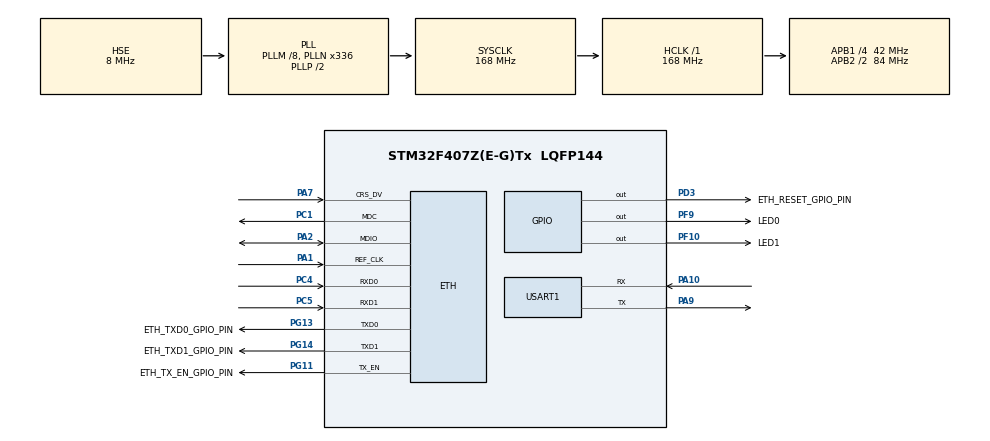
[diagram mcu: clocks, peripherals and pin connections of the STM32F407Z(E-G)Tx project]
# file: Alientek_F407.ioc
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ETH.MediaInterface=HAL_ETH_RMII_MODE
FREERTOS.Tasks01=defaultTask,24,128,StartDefaultTask,Default,NULL,Dynamic,NULL,NULL;myTask02,26,256,StartTask02,As weak,NULL,Static,myTask02Buffer,myTask02ControlBlock;myTask03,27,256,StartTask03,As weak,NULL,Static,myTask03Buffer,myTask03ControlBlock;myTask04,28,512,StartTask04,As weak,NULL,Static,myTask04Buffer,myTask04ControlBlock
FREERTOS.configENABLE_FPU=1
FREERTOS.configMAX_PRIORITIES=32
FREERTOS.configUSE_IDLE_HOOK=1
Mcu.Family=STM32F4
Mcu.Name=STM32F407Z(E-G)Tx
Mcu.Package=LQFP144
NVIC.PriorityGroup=NVIC_PRIORITYGROUP_4
NVIC.TIM1_TRG_COM_TIM11_IRQn=true\:5\:0\:false\:false\:true\:true\:true\:true\:true
NVIC.TIM6_DAC_IRQn=true\:15\:0\:false\:false\:true\:false\:false\:true\:true
NVIC.TimeBase=TIM6_DAC_IRQn
NVIC.TimeBaseIP=TIM6
PA1.Mode=RMII
PA1.Signal=ETH_REF_CLK
PA10.Mode=Asynchronous
PA10.Signal=USART1_RX
PA13.Mode=Trace_Asynchronous_SW
PA13.Signal=SYS_JTMS-SWDIO
PA14.Mode=Trace_Asynchronous_SW
PA14.Signal=SYS_JTCK-SWCLK
PA2.Mode=RMII
PA2.Signal=ETH_MDIO
PA7.Mode=RMII
PA7.Signal=ETH_CRS_DV
PA9.Mode=Asynchronous
PA9.Signal=USART1_TX
PB3.Mode=Trace_Asynchronous_SW
PB3.Signal=SYS_JTDO-SWO
PC1.Mode=RMII
PC1.Signal=ETH_MDC
PC14-OSC32_IN.Mode=LSE-External-Oscillator
PC14-OSC32_IN.Signal=RCC_OSC32_IN
PC15-OSC32_OUT.Mode=LSE-External-Oscillator
PC15-OSC32_OUT.Signal=RCC_OSC32_OUT
PC4.Mode=RMII
PC4.Signal=ETH_RXD0
PC5.Mode=RMII
PC5.Signal=ETH_RXD1
PD3.GPIO_Label=ETH_RESET_GPIO_PIN
PD3.GPIO_Speed=GPIO_SPEED_FREQ_MEDIUM
PD3.PinState=GPIO_PIN_SET
PD3.Signal=GPIO_Output
PF10.GPIO_Label=LED1
PF10.GPIO_Speed=GPIO_SPEED_FREQ_MEDIUM
PF10.PinState=GPIO_PIN_SET
PF10.Signal=GPIO_Output
PF9.GPIO_Label=LED0
PF9.GPIO_Speed=GPIO_SPEED_FREQ_MEDIUM
PF9.PinState=GPIO_PIN_SET
PF9.Signal=GPIO_Output
PG11.GPIO_Label=ETH_TX_EN_GPIO_PIN
PG11.Mode=RMII
PG11.Signal=ETH_TX_EN
PG13.GPIO_Label=ETH_TXD0_GPIO_PIN
PG13.Mode=RMII
PG13.Signal=ETH_TXD0
PG14.GPIO_Label=ETH_TXD1_GPIO_PIN
PG14.Mode=RMII
PG14.Signal=ETH_TXD1
PH0-OSC_IN.Mode=HSE-External-Oscillator
PH0-OSC_IN.Signal=RCC_OSC_IN
PH1-OSC_OUT.Mode=HSE-External-Oscillator
PH1-OSC_OUT.Signal=RCC_OSC_OUT
ProjectManager.HeapSize=0x800
ProjectManager.StackSize=0x800
ProjectManager.TargetToolchain=MDK-ARM V5.32
RCC.48MHZClocksFreq_Value=84000000
RCC.AHBFreq_Value=168000000
RCC.APB1CLKDivider=RCC_HCLK_DIV4
RCC.APB1Freq_Value=42000000
RCC.APB1TimFreq_Value=84000000
RCC.APB2CLKDivider=RCC_HCLK_DIV2
RCC.APB2Freq_Value=84000000
RCC.APB2TimFreq_Value=168000000
RCC.CortexFreq_Value=168000000
RCC.HCLKFreq_Value=168000000
RCC.HSE_VALUE=8000000
RCC.HSI_VALUE=16000000
RCC.PLLM=8
RCC.PLLN=336
RCC.PLLSourceVirtual=RCC_PLLSOURCE_HSE
RCC.SYSCLKFreq_VALUE=168000000
RCC.SYSCLKSource=RCC_SYSCLKSOURCE_PLLCLK
RCC.VCOOutputFreq_Value=336000000
TIM11.Period=4200-1
USART1.VirtualMode=VM_ASYNC
VP_FREERTOS_VS_CMSIS_V2.Mode=CMSIS_V2
VP_SYS_VS_tim6.Mode=TIM6
VP_TIM11_VS_ClockSourceINT.Mode=Enable_Timer
board=custom

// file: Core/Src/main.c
/* USER CODE BEGIN Header */
/**
  ******************************************************************************
  * @file           : main.c
  * @brief          : Main program body
  ******************************************************************************
  * @attention
  *
  * Copyright (c) 2026 STMicroelectronics.
  * All rights reserved.
  *
  * This software is licensed under terms that can be found in the LICENSE file
  * in the root directory of this software component.
  * If no LICENSE file comes with this software, it is provided AS-IS.
  *
  ******************************************************************************
  */
/* USER CODE END Header */
#include "main.h"
#include "cmsis_os.h"
#include "tim.h"
#include "usart.h"
#include "gpio.h"

void SystemClock_Config(void);
void MX_FREERTOS_Init(void);

int main(void)
{

  /* MCU Configuration--------------------------------------------------------*/

  /* Reset of all peripherals, Initializes the Flash interface and the Systick. */
  HAL_Init();

  /* Configure the system clock */
  SystemClock_Config();

  /* Initialize all configured peripherals */
  MX_GPIO_Init();
  MX_USART1_UART_Init();
  MX_TIM11_Init();

  /* Init scheduler */
  osKernelInitialize();  /* Call init function for freertos objects (in cmsis_os2.c) */
  MX_FREERTOS_Init();

  /* Start scheduler */
  osKernelStart();

  /* We should never get here as control is now taken by the scheduler */

  /* Infinite loop */
  while (1)
  {

  }
}

void SystemClock_Config(void)
{
  RCC_OscInitTypeDef RCC_OscInitStruct = {0};
  RCC_ClkInitTypeDef RCC_ClkInitStruct = {0};

  /** Configure the main internal regulator output voltage
  */
  __HAL_RCC_PWR_CLK_ENABLE();
  __HAL_PWR_VOLTAGESCALING_CONFIG(PWR_REGULATOR_VOLTAGE_SCALE1);

  /** Initializes the RCC Oscillators according to the specified parameters
  * in the RCC_OscInitTypeDef structure.
  */
  RCC_OscInitStruct.OscillatorType = RCC_OSCILLATORTYPE_HSE;
  RCC_OscInitStruct.HSEState = RCC_HSE_ON;
  RCC_OscInitStruct.PLL.PLLState = RCC_PLL_ON;
  RCC_OscInitStruct.PLL.PLLSource = RCC_PLLSOURCE_HSE;
  RCC_OscInitStruct.PLL.PLLM = 8;
  RCC_OscInitStruct.PLL.PLLN = 336;
  RCC_OscInitStruct.PLL.PLLP = RCC_PLLP_DIV2;
  RCC_OscInitStruct.PLL.PLLQ = 4;
  if (HAL_RCC_OscConfig(&RCC_OscInitStruct) != HAL_OK)
  {
    Error_Handler();
  }

  /** Initializes the CPU, AHB and APB buses clocks
  */
  RCC_ClkInitStruct.ClockType = RCC_CLOCKTYPE_HCLK|RCC_CLOCKTYPE_SYSCLK
                              |RCC_CLOCKTYPE_PCLK1|RCC_CLOCKTYPE_PCLK2;
  RCC_ClkInitStruct.SYSCLKSource = RCC_SYSCLKSOURCE_PLLCLK;
  RCC_ClkInitStruct.AHBCLKDivider = RCC_SYSCLK_DIV1;
  RCC_ClkInitStruct.APB1CLKDivider = RCC_HCLK_DIV4;
  RCC_ClkInitStruct.APB2CLKDivider = RCC_HCLK_DIV2;

  if (HAL_RCC_ClockConfig(&RCC_ClkInitStruct, FLASH_LATENCY_5) != HAL_OK)
  {
    Error_Handler();
  }
}

void HAL_TIM_PeriodElapsedCallback(TIM_HandleTypeDef *htim)
{
  if (htim->Instance == TIM6)
  {
    HAL_IncTick();
  }
}

void Error_Handler(void)
{
  __disable_irq();
  while (1)
  {
  }
}

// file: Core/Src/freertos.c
/* USER CODE BEGIN Header */
/**
  ******************************************************************************
  * File Name          : freertos.c
  * Description        : Code for freertos applications
  ******************************************************************************
  * @attention
  *
  * Copyright (c) 2026 STMicroelectronics.
  * All rights reserved.
  *
  * This software is licensed under terms that can be found in the LICENSE file
  * in the root directory of this software component.
  * If no LICENSE file comes with this software, it is provided AS-IS.
  *
  ******************************************************************************
  */
/* USER CODE END Header */

#include "FreeRTOS.h"
#include "task.h"
#include "main.h"
#include "cmsis_os.h"

typedef StaticTask_t osStaticThreadDef_t;

/* Definitions for defaultTask */
osThreadId_t defaultTaskHandle;
const osThreadAttr_t defaultTask_attributes = {
  .name = "defaultTask",
  .stack_size = 128 * 4,
  .priority = (osPriority_t) osPriorityNormal,
};
/* Definitions for myTask02 */
osThreadId_t myTask02Handle;
uint32_t myTask02Buffer[ 256 ];
osStaticThreadDef_t myTask02ControlBlock;
const osThreadAttr_t myTask02_attributes = {
  .name = "myTask02",
  .cb_mem = &myTask02ControlBlock,
  .cb_size = sizeof(myTask02ControlBlock),
  .stack_mem = &myTask02Buffer[0],
  .stack_size = sizeof(myTask02Buffer),
  .priority = (osPriority_t) osPriorityNormal2,
};
/* Definitions for myTask03 */
osThreadId_t myTask03Handle;
uint32_t myTask03Buffer[ 256 ];
osStaticThreadDef_t myTask03ControlBlock;
const osThreadAttr_t myTask03_attributes = {
  .name = "myTask03",
  .cb_mem = &myTask03ControlBlock,
  .cb_size = sizeof(myTask03ControlBlock),
  .stack_mem = &myTask03Buffer[0],
  .stack_size = sizeof(myTask03Buffer),
  .priority = (osPriority_t) osPriorityNormal3,
};
/* Definitions for myTask04 */
osThreadId_t myTask04Handle;
uint32_t myTask04Buffer[ 512 ];
osStaticThreadDef_t myTask04ControlBlock;
const osThreadAttr_t myTask04_attributes = {
  .name = "myTask04",
  .cb_mem = &myTask04ControlBlock,
  .cb_size = sizeof(myTask04ControlBlock),
  .stack_mem = &myTask04Buffer[0],
  .stack_size = sizeof(myTask04Buffer),
  .priority = (osPriority_t) osPriorityNormal4,
};

void StartDefaultTask(void *argument);
void StartTask02(void *argument);
void StartTask03(void *argument);
void StartTask04(void *argument);

void MX_FREERTOS_Init(void); /* (MISRA C 2004 rule 8.1) */

/* Hook prototypes */
void vApplicationIdleHook(void);

void MX_FREERTOS_Init(void) {

  /* Create the thread(s) */
  /* creation of defaultTask */
  defaultTaskHandle = osThreadNew(StartDefaultTask, NULL, &defaultTask_attributes);

  /* creation of myTask02 */
  myTask02Handle = osThreadNew(StartTask02, NULL, &myTask02_attributes);

  /* creation of myTask03 */
  myTask03Handle = osThreadNew(StartTask03, NULL, &myTask03_attributes);

  /* creation of myTask04 */
  myTask04Handle = osThreadNew(StartTask04, NULL, &myTask04_attributes);

}

void StartDefaultTask(void *argument)
{
  /* USER CODE BEGIN StartDefaultTask */
  /* Infinite loop */
  for(;;)
  {
    LED0_TOG;
    LED1_TOG;
    osDelay(200);
  }
  /* USER CODE END StartDefaultTask */
}

__weak void StartTask02(void *argument)
{
  for(;;)
  {
    osDelay(1);
  }
}

__weak void StartTask03(void *argument)
{
  for(;;)
  {
    osDelay(1);
  }
}

__weak void StartTask04(void *argument)
{
  for(;;)
  {
    osDelay(1);
  }
}
